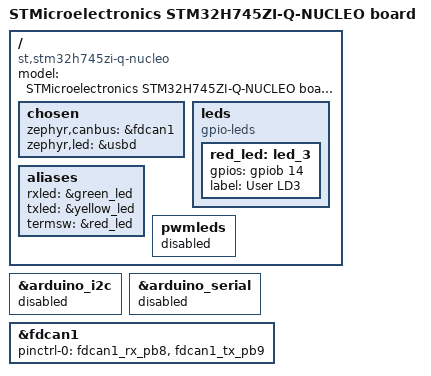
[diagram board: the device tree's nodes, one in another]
/*
 * Copyright (c) 2023 Alexander Kozhinov
 *
 * SPDX-License-Identifier: Apache-2.0
 */

/ {
	model = "STMicroelectronics STM32H745ZI-Q-NUCLEO board";
	compatible = "st,stm32h745zi-q-nucleo";

	chosen {
		zephyr,canbus = &fdcan1;
		zephyr,led = &usbd;
	};

	leds: leds {
		compatible = "gpio-leds";
		red_led: led_3 {
			gpios = <&gpiob 14 GPIO_ACTIVE_HIGH>;
			label = "User LD3";
		};
	};

	aliases {
		rxled = &green_led;
		txled = &yellow_led;
		termsw = &red_led;
	};

	pwmleds {
		status = "disabled";
	};
};

&arduino_i2c {
	status = "disabled";
};

&arduino_serial {
	status = "disabled";
};

// ToDo: Remove clocks entry on PR!
&fdcan1 {
	pinctrl-0 = <&fdcan1_rx_pb8 &fdcan1_tx_pb9>;
	// HSE will be used by default. Uncomment below to enable APB1.2 120MHz clock
	// clocks = <&rcc STM32_CLOCK_BUS_APB1_2 0x00000100>,
	// 	 	 <&rcc STM32_SRC_PLL1_Q FDCAN_SEL(1)>;
	status = "okay";
};
